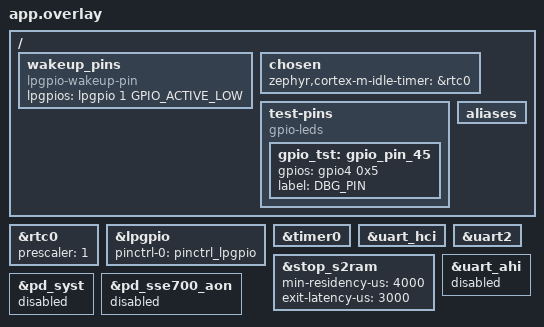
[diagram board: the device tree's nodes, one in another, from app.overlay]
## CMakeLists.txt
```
# Copyright (C) Alif Semiconductor - All Rights Reserved.
# Use, distribution and modification of this code is permitted under the
# terms stated in the Alif Semiconductor Software License Agreement
#
# You should have received a copy of the Alif Semiconductor Software
# License Agreement with this file. If not, please write to:
# contact@alifsemi.com, or visit: https://alifsemi.com/license

cmake_minimum_required(VERSION 3.20.0)
find_package(Zephyr REQUIRED HINTS $ENV{ZEPHYR_BASE})
project(ble_testapp)

target_sources(app PRIVATE
    src/main.c
    src/appl_shell.c
    src/power_mgr.c
    src/ble_handler.c
    src/power_shell.c
)
```

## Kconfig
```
# Copyright (C) Alif Semiconductor - All Rights Reserved.
# Use, distribution and modification of this code is permitted under the
# terms stated in the Alif Semiconductor Software License Agreement
#
# You should have received a copy of the Alif Semiconductor Software
# License Agreement with this file. If not, please write to:
# contact@alifsemi.com, or visit: https://alifsemi.com/license

source "Kconfig.zephyr"

config DATA_STRING_LENGTH
	int "Data string size"
	range 5 250
	default 243
	help
	  Defines how many bytes will be sent in a notification


menu "Logging"

module = MAIN
module-str = main
source "subsys/logging/Kconfig.template.log_config"

endmenu # "Logging"
```

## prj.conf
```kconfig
# Copyright (C) Alif Semiconductor - All Rights Reserved.
# Use, distribution and modification of this code is permitted under the
# terms stated in the Alif Semiconductor Software License Agreement
#
# You should have received a copy of the Alif Semiconductor Software
# License Agreement with this file. If not, please write to:
# contact@alifsemi.com, or visit: https://alifsemi.com/license

CONFIG_BT=y
CONFIG_BT_CUSTOM=y
CONFIG_ASSERT=y
CONFIG_IDLE_STACK_SIZE=2048
CONFIG_COUNTER=y

CONFIG_COUNTER_RTC_SNPS_DW=y
CONFIG_ALIF_POWER_MGR_SHELL=y

CONFIG_PM=y
CONFIG_PM_DEVICE=y
CONFIG_POWER_DOMAIN=y
CONFIG_PM_S2RAM=y
CONFIG_PM_SAU_SAVE_RESTORE=y

CONFIG_SYS_CLOCK_TICKS_PER_SEC=1000
CONFIG_STDOUT_CONSOLE=y
CONFIG_PRINTK=y
CONFIG_POWEROFF=y
CONFIG_BOOT_BANNER=n

CONFIG_SHELL=y
CONFIG_SHELL_AUTOSTART=n
CONFIG_ALIF_TESTCOMMANDS_SHELL=y

CONFIG_LOG=y
# application logging level
CONFIG_MAIN_LOG_LEVEL_INF=y

CONFIG_ALIF_PM_SLEEP_ENABLE=1

####### Configuration supported with the upddated Secure Enclave software
CONFIG_ALIF_EXT_WAKEUP_TIME=0
CONFIG_ALIF_OSC_WAKEUP_TIME=1700
CONFIG_ALIF_RM_WAKEUP_TIME=0
CONFIG_ALIF_EXT_WARMBOOT_WAKEUP_TIME=1700
CONFIG_SE_SERVICE_INIT_PRIORITY=1
CONFIG_KERNEL_INIT_PRIORITY_DEFAULT=0
CONFIG_GPIO_INIT_PRIORITY=40

CONFIG_ALIF_MAX_SLEEP_CLOCK_DRIFT=252
CONFIG_ALIF_MAX_ACTIVE_CLOCK_DRIFT=252

CONFIG_DATA_STRING_LENGTH=243
CONFIG_CORTEX_M_SYSTICK_LPM_TIMER_HOOKS=y

# Increase shell max commands so that we can set run_cfg and off_cfg
CONFIG_SHELL_ARGC_MAX=32
CONFIG_SHELL_CMD_BUFF_SIZE=384
```

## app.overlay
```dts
/* Copyright (C) Alif Semiconductor - All Rights Reserved.
 * Use, distribution and modification of this code is permitted under the
 * terms stated in the Alif Semiconductor Software License Agreement
 *
 * You should have received a copy of the Alif Semiconductor Software
 * License Agreement with this file. If not, please write to:
 * contact@alifsemi.com, or visit: https://alifsemi.com/license
 */

&rtc0 {
	/* Set the counter to increment every 1sec */
	prescaler = <1>;
	status = "okay";
};

&lpgpio {
	pinctrl-0 = < &pinctrl_lpgpio >;
	pinctrl-names = "default";
	status = "okay";
};

/ {
	wakeup_pins: wakeup_pins {
		compatible = "lpgpio-wakeup-pin";
		/* Use only P15_1 as p15_0 has some issues */
		lpgpios = <&lpgpio 1 GPIO_ACTIVE_LOW>;
	};
};

/* LPTimer0 */
&timer0 {
	status = "okay";
};

&uart_hci {
	status = "okay";
};

/* Sleep pincontrol needs to be removed as it causes a extra characters on output and input
 */

&uart2 {
	/*clocks = <&clockctrl ALIF_UART2_38M4_CLK>;*/
	status = "okay";
	/delete-property/ pinctrl-1; // = <&pinctrl_uart2_sleep>;
	pinctrl-names = "default";
};

&stop_s2ram {
	min-residency-us = <4000>;
	exit-latency-us = <3000>;
	status = "okay";
};

/ {
	chosen {
		zephyr,cortex-m-idle-timer = &rtc0;
	};

	test-pins {
		/* Use DK's green LED (P4.5) as a debug pin */
		compatible = "gpio-leds";
		gpio_tst: gpio_pin_45 {
			gpios = < &gpio4 0x5 0x0 >;
			label = "DBG_PIN";
		};
	};

	aliases {
		/* Enable this for the debugging output */
		/* debug-pin = &gpio_tst; */
	};
};

/* Disable unused default components */

&uart_ahi {
	status = "disabled";
};

/* TODO: these do nothing... to be resolved */
&pd_syst {
	status = "disabled";
};

&pd_sse700_aon {
	status = "disabled";
};
```

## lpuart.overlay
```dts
/* Copyright (C) Alif Semiconductor - All Rights Reserved.
 * Use, distribution and modification of this code is permitted under the
 * terms stated in the Alif Semiconductor Software License Agreement
 *
 * You should have received a copy of the Alif Semiconductor Software
 * License Agreement with this file. If not, please write to:
 * contact@alifsemi.com, or visit: https://alifsemi.com/license
 */

&uart2 {
	status = "disabled";
};

/* must override default pinctrl to use P7_0 instead of P2_0 for RX */
&pinctrl_lpuart {
	group0 {
		pinmux = <PIN_P7_0__LPUART_RX_B>,
				<PIN_P7_1__LPUART_TX_B>;
	};
};

&lpuart {
	current-speed = <115200>;
	dlf = <13>;
	/*/delete-property/ dlf;*/
	status = "okay";
	/delete-property/ pinctrl-1; // = <&pinctrl_lpuart_sleep>;
	pinctrl-names = "default";
};

/ {
	chosen {
		zephyr,console = &lpuart;
		zephyr,shell-uart = &lpuart;
		zephyr,uart-mcumgr = &lpuart;
	};
};
```

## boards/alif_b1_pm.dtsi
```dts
/*
 * Copyright (c) 2024 Alif Semiconductor
 * SPDX-License-Identifier: Apache-2.0
 */

&rtc0 {
	/* Set the counter to increment every 1sec */
	prescaler = <1>;
	status = "okay";
};

&lpgpio {
	pinctrl-0 = < &pinctrl_lpgpio >;
	pinctrl-names = "default";
	status = "okay";
};

/ {
	wakeup_pins: wakeup_pins {
		compatible = "lpgpio-wakeup-pin";
		/* Use only P15_1 as p15_0 has some issues */
		lpgpios = <&lpgpio 1 GPIO_ACTIVE_LOW>;
	};
};

/* LPTimer0 */
&timer0 {
	status = "okay";
};

&uart_hci {
	status = "okay";
};

&uart2 {
	/*clocks = <&clockctrl ALIF_UART2_38M4_CLK>;*/
	status = "okay";
};

&stop_s2ram {
	min-residency-us = <4000>;
	exit-latency-us = <3000>;
	status = "okay";
};

/ {
	chosen {
		zephyr,cortex-m-idle-timer = &rtc0;
	};

	test-pins {
		/* Use DK's green LED (P4.5) as a debug pin */
		compatible = "gpio-leds";
		gpio_tst: gpio_pin_45 {
			gpios = < &gpio4 0x5 0x0 >;
			label = "DBG_PIN";
		};
	};

	aliases {
		/* Enable this for the debugging output */
		/* debug-pin = &gpio_tst; */
	};
};

/* Disable unused default components */

&uart_ahi {
	status = "disabled";
};

/* TODO: these do nothing... to be resolved */
&pd_syst {
	status = "disabled";
};

&pd_sse700_aon {
	status = "disabled";
};
```

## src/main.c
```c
/* Copyright (C) Alif Semiconductor - All Rights Reserved.
 * Use, distribution and modification of this code is permitted under the
 * terms stated in the Alif Semiconductor Software License Agreement
 *
 * You should have received a copy of the Alif Semiconductor Software
 * License Agreement with this file. If not, please write to:
 * contact@alifsemi.com, or visit: https://alifsemi.com/license
 */

#include <zephyr/kernel.h>
#include <zephyr/logging/log.h>

#include <zephyr/device.h>
#include <zephyr/drivers/gpio.h>
#include <zephyr/init.h>
#include <zephyr/pm/pm.h>
#include <zephyr/pm/policy.h>
#include <zephyr/sys/poweroff.h>
#include <zephyr/drivers/counter.h>
#include <zephyr/drivers/uart.h>
#include <cmsis_core.h>
#include <soc_common.h>
#include <se_service.h>
#include <es0_power_manager.h>

#include "ke_mem.h"

#include "appl_shell.h"
#include "power_mgr.h"
#include "ble_handler.h"

#if !defined(CONFIG_SOC_SERIES_B1)
#error "Application works only with B1 devices"
#endif

static volatile bool wakeup_status;
static volatile int run_profile_error;

/* Macros */
LOG_MODULE_REGISTER(main, CONFIG_MAIN_LOG_LEVEL);

/*
 * CRITICAL: Must run at PRE_KERNEL_1 to restore SYSTOP before peripherals initialize.
 *
 * On cold boot: SYSTOP is already ON by default, safe to call.
 * On SOFT_OFF wakeup: SYSTOP is OFF, must restore BEFORE peripherals access registers.
 */
SYS_INIT(app_set_run_params, PRE_KERNEL_1, 3);

/**
 * PM Notifier callback for power state entry
 */
static void pm_notify_state_entry(enum pm_state const state)
{
	/* TODO: enable when this is needed */
	/*
	 * const struct pm_state_info *next_state = pm_state_next_get(0);
	 * uint8_t substate_id = next_state ? next_state->substate_id : 0;
	 */

	switch (state) {
	case PM_STATE_SUSPEND_TO_RAM:
	case PM_STATE_SOFT_OFF:
		break;
	default:
		__ASSERT(false, "Entering unknown power state %d", state);
		LOG_ERR("Entering unknown power state %d", state);
		break;
	}
}

/**
 * PM Notifier callback called BEFORE devices are resumed
 *
 * This restores SE run configuration when resuming from S2RAM states.
 * Note: For SOFT_OFF, the system resets completely and app_set_run_params()
 * runs during normal PRE_KERNEL_1 initialization, so this callback is not needed.
 */
static void pm_notify_pre_device_resume(enum pm_state const state)
{
	wakeup_status = get_wakeup_irq_status();

	switch (state) {
	case PM_STATE_SUSPEND_TO_RAM: {
		run_profile_error = app_set_run_params();
		break;
	}
	case PM_STATE_SOFT_OFF: {
		/* No action needed - SOFT_OFF causes reset, not resume */
		break;
	}
	default: {
		__ASSERT(false, "Pre-resume for unknown power state %d", state);
		LOG_ERR("Pre-resume for unknown power state %d", state);
		break;
	}
	}
}

/**
 * PM Notifier structure
 */
static struct pm_notifier app_pm_notifier = {
	.state_entry = pm_notify_state_entry,
	.pre_device_resume = pm_notify_pre_device_resume,
};

/*
 * This function will be invoked in the PRE_KERNEL_1 phase of the init
 * routine to prevent sleep during startup.
 */
static int app_pre_kernel_init(void)
{
	/* Register PM notifier callbacks */
	pm_notifier_register(&app_pm_notifier);

	app_prevent_off();

	return 0;
}
SYS_INIT(app_pre_kernel_init, PRE_KERNEL_1, 39);

#if defined(CONFIG_CORTEX_M_SYSTICK_LPM_TIMER_HOOKS)

static uint32_t idle_timer_pre_idle;

/* Idle timer used for timer while entering the idle state */
static const struct device *idle_timer = DEVICE_DT_GET(DT_CHOSEN(zephyr_cortex_m_idle_timer));
/**
 * To simplify the driver, implement the callout to Counter API
 * as hooks that would be provided by platform drivers if
 * CONFIG_CORTEX_M_SYSTICK_LPM_TIMER_HOOKS was selected instead.
 */
void z_cms_lptim_hook_on_lpm_entry(uint64_t max_lpm_time_us)
{

	/* Store current value of the selected timer to calculate a
	 * difference in measurements after exiting the idle state.
	 */
	counter_get_value(idle_timer, &idle_timer_pre_idle);
	/**
	 * Disable the counter alarm in case it was already running.
	 */
	/* counter_cancel_channel_alarm(idle_timer, 0); */

	/* Set the alarm using timer that runs the idle.
	 * Needed rump-up/setting time, lower accurency etc. should be
	 * included in the exit-latency in the power state definition.
	 */

	struct counter_alarm_cfg cfg = {
		.callback = NULL,
		.ticks = counter_us_to_ticks(idle_timer, max_lpm_time_us) + idle_timer_pre_idle,
		.user_data = NULL,
		.flags = COUNTER_ALARM_CFG_ABSOLUTE,
	};
	counter_set_channel_alarm(idle_timer, 0, &cfg);
}

uint64_t z_cms_lptim_hook_on_lpm_exit(void)
{
	/**
	 * Calculate how much time elapsed according to counter.
	 */
	uint32_t idle_timer_post, idle_timer_diff;

	counter_get_value(idle_timer, &idle_timer_post);

	/**
	 * Check for counter timer overflow
	 * (TODO: this doesn't work for downcounting timers!)
	 */
	if (idle_timer_pre_idle > idle_timer_post) {
		idle_timer_diff = (counter_get_top_value(idle_timer) - idle_timer_pre_idle) +
				  idle_timer_post + 1;
	} else {
		idle_timer_diff = idle_timer_post - idle_timer_pre_idle;
	}

	return (uint64_t)counter_ticks_to_us(idle_timer, idle_timer_diff);
}
#endif /* CONFIG_CORTEX_M_SYSTICK_LPM_TIMER_COUNTER */

int main(void)
{
	if (is_cold_boot()) {
		int ret = pwm_init();

		if (ret) {
			LOG_ERR("pwm_init failed: %d", ret);
			return ret;
		}

		ret = set_off_profile(PM_STATE_MODE_STOP);

		if (ret) {
			LOG_ERR("off profile set failed. error: %d", ret);
			return ret;
		}
		printk("BLE testapp cold start\n");
	}

	appl_wait_to_continue();

	int ret = ble_init();

	if (ret) {
		return ret;
	}

	if (appl_allow_sleep()) {
		app_ready_for_sleep();
	}

	while (1) {
		/* checks for whether sleep period is done */
		appl_allow_sleep();

		if (!ble_is_connected()) {
			k_sleep(K_MSEC(ble_rtc_connected_wakeup));
		} else {
			k_sleep(K_MSEC(ble_rtc_wakeup));
		}
	}
	return 0;
}
```

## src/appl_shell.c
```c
/* Copyright (C) Alif Semiconductor - All Rights Reserved.
 * Use, distribution and modification of this code is permitted under the
 * terms stated in the Alif Semiconductor Software License Agreement
 *
 * You should have received a copy of the Alif Semiconductor Software
 * License Agreement with this file. If not, please write to:
 * contact@alifsemi.com, or visit: https://alifsemi.com/license
 */

#include <zephyr/kernel.h>
#include <zephyr/shell/shell.h>
#include <zephyr/shell/shell_uart.h>
#include <zephyr/logging/log.h>
#include <stdlib.h>
#include "power_mgr.h"
#include "ble_handler.h"

LOG_MODULE_DECLARE(main, CONFIG_MAIN_LOG_LEVEL);

static struct k_sem waiting_semaphore;
static bool __attribute__((noinit)) force_ble_restart;
static bool __attribute__((noinit)) skip_wait;
static uint32_t __attribute__((noinit)) wakeup_time;

uint32_t ble_rtc_wakeup __attribute__((noinit));
uint32_t ble_rtc_connected_wakeup __attribute__((noinit));
uint16_t reset_after_sleep __attribute__((noinit));
enum lp_counter_source counter_source = -1;

void appl_shell_reset(void)
{
	skip_wait = false;
	force_ble_restart = false;
	wakeup_time = 0;
	ble_adv_int_min = 1000;
	ble_adv_int_max = 1000;
	ble_conn_int_min = 800;
	ble_conn_int_max = 800;
	ble_rtc_wakeup = 20000;
	strncpy(app_shell_device_name, "APPL_SHL", DEVICE_NAME_LEN - 1);
	app_shell_device_name[8] = 0;
	reset_after_sleep = 0;
}

void appl_shell_init(void)
{
	/* Mark a cold boot */
	appl_shell_reset();
	k_sem_init(&waiting_semaphore, 0, 1);
}

static int app_shell_init(void)
{
	/* If we are sleeping dont set the shell prompt off */
	const struct shell *shell = shell_backend_uart_get_ptr();

	if (!shell) {
		return 0;
	}
	shell_start(shell);
	appl_shell_init();

	return 0;
}

SYS_INIT(app_shell_init, APPLICATION, 1);

int64_t param_get_int(size_t argc, char **argv, char *p_param, int def_value)
{
	if (p_param && argc > 1) {
		for (int n = 0; n < (argc - 1); n++) {
			if (strcmp(argv[n], p_param) == 0) {
				return strtoll(argv[n + 1], NULL, 0);
			}
		}
	}
	return def_value;
}

char *param_get_char(size_t argc, char **argv, char *p_param, char *def_value)
{
	if (p_param && argc > 1) {
		for (int n = 0; n < (argc - 1); n++) {
			if (strcmp(argv[n], p_param) == 0) {
				return argv[n + 1];
			}
		}
	}
	return def_value;
}

void appl_wait_to_continue(void)
{
	const struct shell *shell = shell_backend_uart_get_ptr();

	shell_print(shell, "BLE testapp started!\n");

	if (!skip_wait) {
		k_sem_take(&waiting_semaphore, K_FOREVER);
		LOG_INF("continuing.");
	}
}

/**
 * Application command functions
 **/
static int cmd_adv_int(const struct shell *shell, size_t argc, char **argv)
{
	ble_adv_int_min = param_get_int(argc, argv, "--min", ble_adv_int_min);
	ble_adv_int_max = param_get_int(argc, argv, "--max", ble_adv_int_max);

	shell_fprintf(shell, SHELL_VT100_COLOR_DEFAULT,
			"set advertisement interval min: %d max %d\n",
			ble_adv_int_min, ble_adv_int_max);
	return 0;
}
static int cmd_conn_int(const struct shell *shell, size_t argc, char **argv)
{
	ble_conn_int_min = param_get_int(argc, argv, "--min", ble_conn_int_min);
	ble_conn_int_max = param_get_int(argc, argv, "--max", ble_conn_int_max);

	shell_fprintf(shell, SHELL_VT100_COLOR_DEFAULT, "set connection interval min: %d max %d\n",
		      ble_conn_int_min, ble_conn_int_max);
	return 0;
}

static int cmd_int(const struct shell *shell, size_t argc, char **argv)
{
	unsigned long wakeup_time = strtoul(argv[1], 0, 10);

	if (wakeup_time) {
		ble_rtc_wakeup = wakeup_time;
	}
	ble_rtc_connected_wakeup =
		param_get_int(argc, argv, "--connected", ble_rtc_connected_wakeup);

	shell_fprintf(shell, SHELL_VT100_COLOR_DEFAULT, "set RTC wakeup: %d when connected %d\n",
		      ble_rtc_wakeup, ble_rtc_connected_wakeup);
	return 0;
}

static int cmd_continue(const struct shell *shell, size_t argc, char **argv)
{
	reset_after_sleep = param_get_int(argc, argv, "--reset_after", reset_after_sleep);
	skip_wait = true;
	k_sem_give(&waiting_semaphore);
	shell_print(shell, "BLEtestapp continue");
	return 0;
}

void appl_shell_sleep_period_end(void)
{
	if (reset_after_sleep) {
		const struct shell *shell = shell_backend_uart_get_ptr();
		int ret;

		appl_shell_reset();
		ret = ble_uninit();
		shell_print(shell, "BLE application is restarted %d", ret);
	}
}

static int cmd_sleep(const struct shell *shell, size_t argc, char **argv)
{
	uint32_t sleeptime_s = strtoul(argv[1], 0, 10);

	shell_print(shell, "start sleep cycle %d s", sleeptime_s);

	app_sleep_start(sleeptime_s);
	return 0;
}

static int cmd_set_name(const struct shell *shell, size_t argc, char **argv)
{
	if (skip_wait) {
		shell_error(shell, "Name must be set on POR, before continue is called.");
		return -ENOEXEC;
	}
	/* app_shell_device_name has null-ending as per cold boot init */
	strncpy(app_shell_device_name, argv[1],	DEVICE_NAME_LEN - 1);
	shell_print(shell, "BLE name set to %s", app_shell_device_name);
	return 0;
}

static int cmd_select_timer(const struct shell *shell, size_t argc, char **argv)
{
	if (!strcmp(argv[1], "LPRTC")) {
		counter_source = LPRTC;
		shell_print(shell, "Selected LPRTC as wakeup source");
	} else if (!strcmp(argv[1], "LPTIMER")) {
		counter_source = LPTIMER;
		shell_print(shell, "Selected LPTIMER as wakeup source");
	} else {
		shell_error(shell, "Select timer source from LPRTC and LPTIMER");
		return -ENOEXEC;
	}
	return 0;
}


static int cmd_set_offprofile(const struct shell *shell, size_t argc, char **argv)
{
	int ret;

	if (!strcmp(argv[1], "STOP")) {
		ret = set_off_profile(PM_STATE_MODE_STOP_1);

		if (ret) {
			shell_error(shell, "Failed to set off profile: %d", ret);
			return -ENOEXEC;
		}
		shell_print(shell, "Off profile set to STOP");
	} else if (!strcmp(argv[1], "IDLE")) {
		set_off_profile_configuration(PM_STATE_MODE_IDLE_1);
		current_offp.power_domains |= PD_SESS_MASK;
		ret = set_current_off_profile();

		if (ret) {
			shell_error(shell, "Failed to set off profile: %d", ret);
			return -ENOEXEC;
		}
		shell_print(shell, "Off profile set to IDLE");
	} else if (!strcmp(argv[1], "STANDBY")) {
		ret = set_off_profile(PM_STATE_MODE_STANDBY_1);

		if (ret) {
			shell_error(shell, "Failed to set off profile: %d", ret);
			return -ENOEXEC;
		}
		shell_print(shell, "Off profile set to STANDBY");
	} else {
		shell_error(shell, "Select off profile from STOP, IDLE, STANDBY");
		return -ENOEXEC;
	}
	return 0;
}

SHELL_STATIC_SUBCMD_SET_CREATE(
	sub_cmds,
	SHELL_CMD_ARG(adv-interval, NULL,
		      "configure advertisement interval --min <slots> --max <slots>", cmd_adv_int,
		      1, 10),
	SHELL_CMD_ARG(conn-interval, NULL,
		      "configure connection interval --min <slots> --max <slots>", cmd_conn_int, 1,
		      10),
	SHELL_CMD_ARG(interval, NULL,
		      "configure M55 wakeup interval <time in ms> --connected <time in ms>",
		      cmd_int, 1, 10),
	SHELL_CMD_ARG(continue, NULL, "Start ble application --reset_after <0/1>",
		cmd_continue, 1, 10),
	SHELL_CMD_ARG(sleep, NULL, "allow sleep in <seconds>", cmd_sleep, 2, 10),
	SHELL_CMD_ARG(init, NULL, "BLE stack initialize", cmd_sleep, 2, 10),
	SHELL_CMD_ARG(set-name, NULL, "set name for BLE <name>", cmd_set_name, 2, 10),
	SHELL_CMD_ARG(set_offprofile, NULL, "Set off profile", cmd_set_offprofile, 2, 10),
	SHELL_CMD_ARG(select_timer, NULL, "Select timer source <LPRTC/LPTIMER>",
		cmd_select_timer, 2, 10),
	SHELL_SUBCMD_SET_END);

SHELL_CMD_REGISTER(ble_appl, &sub_cmds, "Ble configuration commands", NULL);
```

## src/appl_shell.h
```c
/* Copyright (C) Alif Semiconductor - All Rights Reserved.
 * Use, distribution and modification of this code is permitted under the
 * terms stated in the Alif Semiconductor Software License Agreement
 *
 * You should have received a copy of the Alif Semiconductor Software
 * License Agreement with this file. If not, please write to:
 * contact@alifsemi.com, or visit: https://alifsemi.com/license
 */

extern uint16_t ble_adv_int_min;
extern uint16_t ble_adv_int_max;
extern uint16_t ble_conn_int_min;
extern uint16_t ble_conn_int_max;
extern uint32_t ble_rtc_wakeup;
extern uint32_t ble_rtc_connected_wakeup;
extern char app_shell_device_name[];

void appl_wait_to_continue(void);
bool appl_allow_sleep(void);
void cmd_appl_shell_init(void);
bool appl_restart_ble(void);
```

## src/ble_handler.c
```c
/* Copyright (C) Alif Semiconductor - All Rights Reserved.
 * Use, distribution and modification of this code is permitted under the
 * terms stated in the Alif Semiconductor Software License Agreement
 *
 * You should have received a copy of the Alif Semiconductor Software
 * License Agreement with this file. If not, please write to:
 * contact@alifsemi.com, or visit: https://alifsemi.com/license
 */

#include "ble_handler.h"

#include <errno.h>
#include <zephyr/kernel.h>
#include <zephyr/logging/log.h>

#include <se_service.h>
#include "alif_ble.h"
#include "gapm.h"
#include "gap_le.h"
#include "gapc_le.h"
#include "gapc_sec.h"
#include "gapm_le.h"
#include "gapm_le_adv.h"
#include "co_buf.h"
#include "prf.h"
#include "gatt_db.h"
#include "gatt_srv.h"

#include "appl_shell.h"
#include <zephyr/shell/shell.h>
#include <zephyr/shell/shell_uart.h>
#include <alif/bluetooth/bt_adv_data.h>
#include <alif/bluetooth/bt_scan_rsp.h>
#include "gapm_api.h"

LOG_MODULE_DECLARE(main, CONFIG_MAIN_LOG_LEVEL);

static uint8_t hello_arr[] = "HelloHello";
static uint8_t hello_arr_index __attribute__((noinit));

/* BLE configurations*/
char __attribute__((noinit)) app_shell_device_name[DEVICE_NAME_LEN];

uint16_t ble_adv_int_min __attribute__((noinit));
uint16_t ble_adv_int_max __attribute__((noinit));
uint16_t ble_conn_int_min __attribute__((noinit));
uint16_t ble_conn_int_max __attribute__((noinit));

/* Service Definitions */
#define ATT_128_PRIMARY_SERVICE    ATT_16_TO_128_ARRAY(GATT_DECL_PRIMARY_SERVICE)
#define ATT_128_INCLUDED_SERVICE   ATT_16_TO_128_ARRAY(GATT_DECL_INCLUDE)
#define ATT_128_CHARACTERISTIC     ATT_16_TO_128_ARRAY(GATT_DECL_CHARACTERISTIC)
#define ATT_128_CLIENT_CHAR_CFG    ATT_16_TO_128_ARRAY(GATT_DESC_CLIENT_CHAR_CFG)
/* HELLO SERVICE and attribute 128 bit UUIDs */
#define HELLO_UUID_128_SVC                                                                         \
	{0x12, 0x34, 0x56, 0x78, 0x90, 0x12, 0x23, 0x34,                                           \
	 0x45, 0x56, 0x67, 0x78, 0x89, 0x90, 0x00, 0x00}
#define HELLO_UUID_128_CHAR0                                                                       \
	{0x12, 0x34, 0x56, 0x78, 0x90, 0x12, 0x23, 0x34,                                           \
	 0x45, 0x56, 0x67, 0x78, 0x89, 0x15, 0x00, 0x00}
#define HELLO_UUID_128_CHAR1                                                                       \
	{0x12, 0x34, 0x56, 0x78, 0x90, 0x12, 0x23, 0x34,                                           \
	 0x45, 0x56, 0x67, 0x78, 0x89, 0x16, 0x00, 0x00}
#define HELLO_METAINFO_CHAR0_NTF_SEND 0x4321
#define ATT_16_TO_128_ARRAY(uuid)                                                                  \
	{(uuid) & 0xFF, (uuid >> 8) & 0xFF, 0, 0, 0, 0, 0, 0, 0, 0, 0, 0, 0, 0, 0, 0}

/* List of attributes in the service */
enum service_att_list {
	HELLO_IDX_SERVICE = 0,
	/* First characteristic is readable + supports notifications */
	HELLO_IDX_CHAR0_CHAR,
	HELLO_IDX_CHAR0_VAL,
	HELLO_IDX_CHAR0_NTF_CFG,
	/* Second characteristic is writable */
	HELLO_IDX_CHAR1_CHAR,
	HELLO_IDX_CHAR1_VAL,
	/* Number of items*/
	HELLO_IDX_NB,
};

static volatile bool conn_status __attribute__((noinit));
/* Store advertising activity index for re-starting after disconnection */
static volatile uint8_t conn_idx __attribute__((noinit));
static uint8_t adv_actv_idx __attribute__((noinit));
static struct service_env env __attribute__((noinit));

static volatile int run_profile_error;

static const char *device_name = app_shell_device_name;

/* Service UUID to pass into gatt_db_svc_add */
static const uint8_t hello_service_uuid[] = HELLO_UUID_128_SVC;

/* GATT database for the service */
static const gatt_att_desc_t hello_att_db[HELLO_IDX_NB] = {
	[HELLO_IDX_SERVICE] = {ATT_128_PRIMARY_SERVICE, ATT_UUID(16) | PROP(RD), 0},

	[HELLO_IDX_CHAR0_CHAR] = {ATT_128_CHARACTERISTIC, ATT_UUID(16) | PROP(RD), 0},
	[HELLO_IDX_CHAR0_VAL] = {HELLO_UUID_128_CHAR0, ATT_UUID(128) | PROP(RD) | PROP(N),
				 OPT(NO_OFFSET)},
	[HELLO_IDX_CHAR0_NTF_CFG] = {ATT_128_CLIENT_CHAR_CFG, ATT_UUID(16) | PROP(RD) | PROP(WR),
				     0},

	[HELLO_IDX_CHAR1_CHAR] = {ATT_128_CHARACTERISTIC, ATT_UUID(16) | PROP(RD), 0},
	[HELLO_IDX_CHAR1_VAL] = {HELLO_UUID_128_CHAR1, ATT_UUID(128) | PROP(WR),
				 OPT(NO_OFFSET) | sizeof(uint16_t)},
};

/**
 * Bluetooth stack configuration
 */
static gapm_config_t gapm_cfg = {
	.role = GAP_ROLE_LE_PERIPHERAL,
	.pairing_mode = GAPM_PAIRING_DISABLE,
	.privacy_cfg = 0,
	.renew_dur = 1500,
	.private_identity.addr = {0xCF, 0xFE, 0xFB, 0xDE, 0x11, 0x07},
	.irk.key = {0, 0, 0, 0, 0, 0, 0, 0, 0, 0, 0, 0, 0, 0, 0, 0},
	.gap_start_hdl = 0,
	.gatt_start_hdl = 0,
	.att_cfg = 0,
	.sugg_max_tx_octets = GAP_LE_MAX_OCTETS,
	.sugg_max_tx_time = GAP_LE_MAX_TIME,
	.tx_pref_phy = GAP_PHY_ANY,
	.rx_pref_phy = GAP_PHY_ANY,
	.tx_path_comp = 0,
	.rx_path_comp = 0,
	.class_of_device = 0,  /* BT Classic only */
	.dflt_link_policy = 0, /* BT Classic only */
};

/* Environment for the service */
struct service_env {
	uint16_t start_hdl;
	uint8_t user_lid;
	uint8_t char0_val[250];
	uint8_t char1_val;
	volatile bool ntf_ongoing;
	volatile uint16_t ntf_cfg;
};

static gapc_le_con_param_nego_with_ce_len_t app_preferred_connection_param = {.ce_len_min = 5,
									      .ce_len_max = 10,
									      .hdr.interval_min = 0,
									      .hdr.interval_max =
										      10,
									      .hdr.latency = 0,
									      .hdr.sup_to = 800};

/* function headers */
static uint16_t service_init(void);

/* Functions */

int ble_shell_reset(void)
{
	ble_adv_int_min = 1000;
	ble_adv_int_max = 1000;
	ble_conn_int_min = 800;
	ble_conn_int_max = 800;
	strncpy(app_shell_device_name, "test_shl", DEVICE_NAME_LEN - 1);
	app_shell_device_name[8] = 0;
	return 0;
}

SYS_INIT(ble_shell_reset, POST_KERNEL, 91);

/**
 * Bluetooth GAPM callbacks
 */
void on_gapc_proc_cmp_cb(uint8_t conidx, uint32_t metainfo, uint16_t status)
{
	LOG_INF("%s conn:%d status:%d\n", __func__, conidx, status);
}
static void app_connected_handler(uint8_t con_idx)
{
	const struct shell *shell = shell_backend_uart_get_ptr();
	uint16_t ret;

	conn_status = BT_CONN_STATE_CONNECTED;
	conn_idx = con_idx;
	ret = gapc_le_update_params(con_idx, 0, &app_preferred_connection_param,
				    on_gapc_proc_cmp_cb);

	shell_print(shell, "BLE Connected conn:%d", con_idx);
}

void app_connection_status_update(enum gapm_connection_event con_event, uint8_t con_idx,
				  uint16_t status)
{
	const struct shell *shell = shell_backend_uart_get_ptr();

	switch (con_event) {
	case GAPM_API_SEC_CONNECTED_KNOWN_DEVICE:
		app_connected_handler(con_idx);
		break;
	case GAPM_API_DEV_CONNECTED:
		app_connected_handler(con_idx);
		break;
	case GAPM_API_DEV_DISCONNECTED:
		conn_status = BT_CONN_STATE_DISCONNECTED;
		conn_idx = GAP_INVALID_CONIDX;
		shell_print(shell, "BLE disconnected conn:%d. Waiting new connection", con_idx);
		break;
	case GAPM_API_PAIRING_FAIL:
		shell_print(shell, "Connection pairing index %u fail for reason %u", con_idx,
			    status);
		break;
	}
}

static gapm_user_cb_t gapm_user_cb = {
	.connection_status_update = app_connection_status_update,
};

static uint16_t set_advertising_data(uint8_t actv_idx)
{
	bt_adv_data_set_name_auto(device_name, strlen(device_name));

	return bt_gapm_advertiment_data_set(actv_idx);
}

static uint16_t set_scan_data(uint8_t actv_idx)
{
	int ret;

	/* gatt service identifier */
	uint16_t svc[8] = {0xd123, 0xeabc, 0x785f, 0x1523, 0xefde, 0x1212, 0x1523, 0x0000};

	ret = bt_scan_rsp_set_tlv(GAP_AD_TYPE_COMPLETE_LIST_128_BIT_UUID, svc, sizeof(svc));
	if (ret) {
		LOG_ERR("Scan response UUID set fail %d", ret);
		return ATT_ERR_INSUFF_RESOURCE;
	}

	ret = bt_scan_rsp_data_set_name_auto(device_name, strlen(device_name));

	if (ret) {
		LOG_ERR("Scan response device name data fail %d", ret);
		return ATT_ERR_INSUFF_RESOURCE;
	}

	return bt_gapm_scan_response_set(actv_idx);
}

static uint16_t create_advertising(void)
{
	gapm_le_adv_create_param_t adv_create_params = {
		.prop = GAPM_ADV_PROP_UNDIR_CONN_MASK,
		.disc_mode = GAPM_ADV_MODE_GEN_DISC,
		.tx_pwr = 0,
		.filter_pol = GAPM_ADV_ALLOW_SCAN_ANY_CON_ANY,
		.prim_cfg = {
				.adv_intv_min = ble_adv_int_min,
				.adv_intv_max = ble_adv_int_max,
				.ch_map = ADV_ALL_CHNLS_EN,
				.phy = GAPM_PHY_TYPE_LE_1M,
			},
	};

	return bt_gapm_le_create_advertisement_service(GAPM_STATIC_ADDR, &adv_create_params, NULL,
						       &adv_actv_idx);
}

/* Add service to the stack */
static void server_configure(void)
{
	uint16_t err;

	err = service_init();

	if (err) {
		LOG_ERR("Error %u adding profile", err);
	}
}

/* Service callbacks */
static void on_att_read_get(uint8_t conidx, uint8_t user_lid, uint16_t token, uint16_t hdl,
			    uint16_t offset, uint16_t max_length)
{
	co_buf_t *p_buf = NULL;
	uint16_t status = GAP_ERR_NO_ERROR;
	uint16_t att_val_len = 0;
	void *att_val = NULL;

	do {
		if (offset != 0) {
			/* Long read not supported for any characteristics within this service */
			status = ATT_ERR_INVALID_OFFSET;
			break;
		}

		uint8_t att_idx = hdl - env.start_hdl;

		switch (att_idx) {
		case HELLO_IDX_CHAR0_VAL:
			att_val_len = CONFIG_DATA_STRING_LENGTH;
			uint8_t loop_count = (CONFIG_DATA_STRING_LENGTH / 5);

			if (CONFIG_DATA_STRING_LENGTH % 5) {
				loop_count += 1;
			}
			for (int i = 0; i < loop_count; i++) {
				memcpy(env.char0_val + i * 5, &hello_arr[hello_arr_index], 5);
			}
			att_val = env.char0_val;
			LOG_DBG("read hello text");
			break;

		case HELLO_IDX_CHAR0_NTF_CFG:
			att_val_len = sizeof(env.ntf_cfg);
			att_val = (void *)&env.ntf_cfg;
			break;

		default:
			break;
		}

		if (att_val == NULL) {
			status = ATT_ERR_REQUEST_NOT_SUPPORTED;
			break;
		}

		status = co_buf_alloc(&p_buf, GATT_BUFFER_HEADER_LEN, att_val_len,
				      GATT_BUFFER_TAIL_LEN);
		if (status != CO_BUF_ERR_NO_ERROR) {
			status = ATT_ERR_INSUFF_RESOURCE;
			break;
		}

		memcpy(co_buf_data(p_buf), att_val, att_val_len);
	} while (0);

	/* Send the GATT response */
	gatt_srv_att_read_get_cfm(conidx, user_lid, token, status, att_val_len, p_buf);
	if (p_buf != NULL) {
		co_buf_release(p_buf);
	}
}

static void on_att_val_set(uint8_t conidx, uint8_t user_lid, uint16_t token, uint16_t hdl,
			   uint16_t offset, co_buf_t *p_data)
{
	uint16_t status = GAP_ERR_NO_ERROR;

	do {
		if (offset != 0) {
			/* Long write not supported for any characteristics in this service */
			status = ATT_ERR_INVALID_OFFSET;
			break;
		}

		uint8_t att_idx = hdl - env.start_hdl;

		switch (att_idx) {
		case HELLO_IDX_CHAR1_VAL: {
			if (sizeof(env.char1_val) != co_buf_data_len(p_data)) {
				LOG_DBG("Incorrect buffer size");
				status = ATT_ERR_INVALID_ATTRIBUTE_VAL_LEN;
			} else {
				memcpy(&env.char1_val, co_buf_data(p_data), sizeof(env.char1_val));
				LOG_DBG("TOGGLE LED, state %d", env.char1_val);
			}
			break;
		}

		case HELLO_IDX_CHAR0_NTF_CFG: {
			if (sizeof(uint16_t) != co_buf_data_len(p_data)) {
				LOG_DBG("Incorrect buffer size");
				status = ATT_ERR_INVALID_ATTRIBUTE_VAL_LEN;
			} else {
				uint16_t cfg;

				memcpy(&cfg, co_buf_data(p_data), sizeof(uint16_t));
				if (PRF_CLI_START_NTF == cfg || PRF_CLI_STOP_NTFIND == cfg) {
					env.ntf_cfg = cfg;
				} else {
					/* Indications not supported */
					status = ATT_ERR_REQUEST_NOT_SUPPORTED;
				}
			}
			break;
		}

		default:
			status = ATT_ERR_REQUEST_NOT_SUPPORTED;
			break;
		}
	} while (0);

	/* Send the GATT write confirmation */
	gatt_srv_att_val_set_cfm(conidx, user_lid, token, status);
}

static void on_event_sent(uint8_t conidx, uint8_t user_lid, uint16_t metainfo, uint16_t status)
{
	if (metainfo == HELLO_METAINFO_CHAR0_NTF_SEND) {
		env.ntf_ongoing = false;
	}
}

static const gatt_srv_cb_t gatt_cbs = {
	.cb_att_event_get = NULL,
	.cb_att_info_get = NULL,
	.cb_att_read_get = on_att_read_get,
	.cb_att_val_set = on_att_val_set,
	.cb_event_sent = on_event_sent,
};

/*
 * Service functions
 */
static uint16_t service_init(void)
{
	uint16_t status;

	/* Register a GATT user */
	status = gatt_user_srv_register(CFG_MAX_LE_MTU, 0, &gatt_cbs, &env.user_lid);
	if (status != GAP_ERR_NO_ERROR) {
		return status;
	}

	/* Add the GATT service */
	status = gatt_db_svc_add(env.user_lid, SVC_UUID(128), hello_service_uuid, HELLO_IDX_NB,
				 NULL, hello_att_db, HELLO_IDX_NB, &env.start_hdl);
	if (status != GAP_ERR_NO_ERROR) {
		gatt_user_unregister(env.user_lid);
		return status;
	}

	return GAP_ERR_NO_ERROR;
}

int ble_init(void)
{
	/* Update preferred connection parameters */
	app_preferred_connection_param.hdr.interval_min = ble_conn_int_min;
	app_preferred_connection_param.hdr.interval_max = ble_conn_int_max;

	/* Start up bluetooth host stack. */
	uint16_t ble_status = alif_ble_enable(NULL);

	if (ble_status && ble_status != -EALREADY) {
		LOG_ERR("alif_ble_enable error %d", ble_status);
		return -1;
	}
	return 0;
}

int ble_start(void)
{
	uint16_t rc;
	/* BLE initialized first time */
	hello_arr_index = 0;
	conn_idx = GAP_INVALID_CONIDX;
	memset(&env, 0, sizeof(struct service_env));
	conn_status = BT_CONN_STATE_DISCONNECTED;

	/* Set a preferred connections params  */
	bt_gapm_preferred_connection_paras_set(&app_preferred_connection_param);
	/* Generate random address */
	se_service_get_rnd_num(&gapm_cfg.private_identity.addr[3], 3);
	/* Configure Bluetooth Stack */
	LOG_INF("Init gapm service");
	rc = bt_gapm_init(&gapm_cfg, &gapm_user_cb, device_name, strlen(device_name));
	if (rc) {
		LOG_ERR("gapm_configure error %u", rc);
		return -1;
	}

	server_configure();

	/* Create an advertising activity */
	rc = create_advertising();
	if (rc) {
		LOG_ERR("Advertisement create fail %u", rc);
		return -1;
	}

	rc = set_advertising_data(adv_actv_idx);
	if (rc) {
		LOG_ERR("Advertisement data set fail %u", rc);
		return -1;
	}

	rc = set_scan_data(adv_actv_idx);
	if (rc) {
		LOG_ERR("Scan response data set fail %u", rc);
		return -1;
	}

	rc = bt_gapm_advertisement_start(adv_actv_idx);
	if (rc) {
		LOG_ERR("Advertisement start fail %u", rc);
		return -1;
	}

	LOG_INF("start complete!");
	return 0;
}

int ble_uninit(void)
{
	conn_status = BT_CONN_STATE_DISCONNECTED;
	return alif_ble_disable();
}

bool ble_is_connected(void)
{
	return (BT_CONN_STATE_DISCONNECTED == BT_CONN_STATE_CONNECTED);
}

static int cmd_bt_disable(const struct shell *shell, size_t argc, char **argv)
{
	int ret;

	ble_shell_reset();
	ret = ble_uninit();
	shell_print(shell, "BLE application is restarted %d", ret);
	return 0;
}

static int cmd_bt_init(const struct shell *shell, size_t argc, char **argv)
{
	int ret = ble_init();

	shell_print(shell, "BLE stack init %d", ret);
	return 0;
}

static int cmd_bt_name(const struct shell *shell, size_t argc, char **argv)
{
	/* app_shell_device_name has null-ending as per cold boot init */
	strncpy(app_shell_device_name, argv[1], DEVICE_NAME_LEN - 1);
	shell_print(shell, "BLE name set to %s", app_shell_device_name);
	return 0;
}

static int cmd_bt_advertise(const struct shell *shell, size_t argc, char **argv)
{
	int ret;

	ret = ble_start();
	shell_print(shell, "BLE advertisement started %d", ret);
	return 0;
}

SHELL_STATIC_SUBCMD_SET_CREATE(
	sub_cmds,
	SHELL_CMD_ARG(init, NULL, "[none]", cmd_bt_init, 1, 10),
	SHELL_CMD_ARG(advertise, NULL, "<type: off, on, nconn>", cmd_bt_advertise, 1, 10),
	SHELL_CMD_ARG(disable, NULL, "[none]", cmd_bt_disable, 1, 10),
	SHELL_CMD_ARG(name, NULL, "[name]", cmd_bt_name, 2, 10),
	SHELL_SUBCMD_SET_END);
SHELL_CMD_REGISTER(bt, &sub_cmds, "bt - Bluetooth shell commands", NULL);
```

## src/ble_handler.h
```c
/* Copyright (C) Alif Semiconductor - All Rights Reserved.
 * Use, distribution and modification of this code is permitted under the
 * terms stated in the Alif Semiconductor Software License Agreement
 *
 * You should have received a copy of the Alif Semiconductor Software
 * License Agreement with this file. If not, please write to:
 * contact@alifsemi.com, or visit: https://alifsemi.com/license
 */

#include <inttypes.h>
#include <stdbool.h>

#define DEVICE_NAME_LEN 9
extern char app_shell_device_name[];

extern uint16_t ble_adv_int_min;
extern uint16_t ble_adv_int_max;
extern uint16_t ble_conn_int_min;
extern uint16_t ble_conn_int_max;

int ble_init(void);
int ble_start(void);
int ble_uninit(void);
bool ble_is_connected(void);
```

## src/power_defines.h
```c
/* Copyright (C) Alif Semiconductor - All Rights Reserved.
 * Use, distribution and modification of this code is permitted under the
 * terms stated in the Alif Semiconductor Software License Agreement
 *
 * You should have received a copy of the Alif Semiconductor Software
 * License Agreement with this file. If not, please write to:
 * contact@alifsemi.com, or visit: https://alifsemi.com/license
 */
#ifndef __POWER_DEFINES_H__
#define __POWER_DEFINES_H__

#include <zephyr/kernel.h>
#include <aipm.h>

enum lp_counter_source {
	LPRTC,
	LPTIMER,
};

#define SERAM_MEMORY_BLOCKS_IN_USE SERAM_1_MASK | SERAM_2_MASK | SERAM_3_MASK | SERAM_4_MASK

#define APP_RET_MEM_BLOCKS \
	SRAM4_1_MASK | SRAM4_2_MASK | SRAM4_3_MASK | SRAM4_4_MASK | SRAM5_1_MASK | SRAM5_2_MASK |  \
	SRAM5_3_MASK | SRAM5_4_MASK | SRAM5_5_MASK

#if DT_NODE_HAS_COMPAT_STATUS(DT_NODELABEL(timer0), snps_dw_timers, okay)
#define WAKEUP_SOURCE_LPTIMER	DT_NODELABEL(timer0)
#endif
#if DT_NODE_HAS_COMPAT_STATUS(DT_NODELABEL(rtc0), snps_dw_apb_rtc, okay)
#define WAKEUP_SOURCE_RTC		DT_NODELABEL(rtc0)
#endif
#if DT_NODE_HAS_COMPAT_STATUS(DT_NODELABEL(lpgpio), snps_designware_gpio, okay)
#define WAKEUP_SOURCE_LPGPIO	DT_NODELABEL(lpgpio)
#endif

#endif /* __POWER_DEFINES_H__ */
```

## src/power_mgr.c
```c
/* Copyright (C) Alif Semiconductor - All Rights Reserved.
 * Use, distribution and modification of this code is permitted under the
 * terms stated in the Alif Semiconductor Software License Agreement
 *
 * You should have received a copy of the Alif Semiconductor Software
 * License Agreement with this file. If not, please write to:
 * contact@alifsemi.com, or visit: https://alifsemi.com/license
 */

#include <zephyr/kernel.h>
#include <zephyr/logging/log.h>
#include <zephyr/pm/pm.h>
#include <zephyr/pm/policy.h>
#include <zephyr/drivers/counter.h>
#include <zephyr/shell/shell.h>
#include <zephyr/shell/shell_uart.h>
#include <cmsis_core.h>
#include <se_service.h>
#include "power_mgr.h"
#include "power_defines.h"
#include "ble_handler.h"

struct k_timer sleep_end_timer;
void sleep_period_end(struct k_timer *timer_id);
void sleep_period_done(struct k_work *work);

K_WORK_DEFINE(sleep_end_worker, sleep_period_done);

LOG_MODULE_DECLARE(main, CONFIG_MAIN_LOG_LEVEL);

extern enum lp_counter_source counter_source;
static const struct device *wakeup_dev;
static bool counter_started;

run_profile_t current_runp __attribute__((noinit));
off_profile_t current_offp __attribute__((noinit));
int16_t power_profile __attribute__((noinit));

static int power_mgr_init(void)
{
	counter_started = false;
	wakeup_dev = 0;
	return select_timer_source(LPRTC);
}

int select_timer_source(enum lp_counter_source source)
{
	int ret = 0;

	if (counter_source == source) {
		return 0;
	}

	if (counter_started) {
		ret = counter_stop(wakeup_dev);
		if (ret && ret != -EALREADY) {
			printk("failed to stop counter: %d", ret);
			return -1;
		}
		counter_started = false;
	}

	wakeup_dev = 0;

	if (source == LPRTC) {
#ifndef WAKEUP_SOURCE_RTC
		printk("Wakeup Device RTC not enabled in the dts");
		return -1;
#else
		wakeup_dev = DEVICE_DT_GET(WAKEUP_SOURCE_RTC);
#endif
	} else if (source == LPTIMER) {
#ifndef WAKEUP_SOURCE_LPTIMER
		printk("Wakeup Device LPTIMER not enabled in the dts");
		return -1;
#else
		wakeup_dev = DEVICE_DT_GET(WAKEUP_SOURCE_LPTIMER);
#endif
	} else {
		LOG_ERR("Invalid timer source selected");
		return -1;
	}

	if (!device_is_ready(wakeup_dev)) {
		printk("%s: device not ready", wakeup_dev->name);
		return -1;
	}

	ret = counter_start(wakeup_dev);

	if (ret && ret != -EALREADY) {
		printk("failed to start counter: %d", ret);
		return -1;
	}

	counter_source = source;
	counter_started = true;
	get_default_off_cfg(&current_offp);
	ret = set_off_profile(PM_STATE_MODE_STOP_1);

	get_default_run_cfg(&current_runp);

	if (ret) {
		LOG_ERR("off profile set failed. error: %d", ret);
	}
	k_timer_init(&sleep_end_timer, sleep_period_end, NULL);

	return 0;
}
SYS_INIT(power_mgr_init, POST_KERNEL, 99);

void app_ready_for_sleep(void)
{
	pm_policy_state_lock_put(PM_STATE_SOFT_OFF, PM_ALL_SUBSTATES);
	pm_policy_state_lock_put(PM_STATE_SUSPEND_TO_RAM, PM_ALL_SUBSTATES);
}

void app_prevent_off(void)
{
	pm_policy_state_lock_get(PM_STATE_SOFT_OFF, PM_ALL_SUBSTATES);
	pm_policy_state_lock_get(PM_STATE_SUSPEND_TO_RAM, PM_ALL_SUBSTATES);
}

void sleep_period_done(struct k_work *work)
{
	const struct shell *shell = shell_backend_uart_get_ptr();

	shell_print(shell, "sleep period done.");
}

void sleep_period_end(struct k_timer *timer_id)
{
	app_prevent_off();
	k_work_submit(&sleep_end_worker);
}

void app_sleep_start(uint32_t time_s)
{
	k_timer_start(&sleep_end_timer, K_SECONDS(time_s), K_NO_WAIT);
	app_ready_for_sleep();
}

int set_current_off_profile(void)
{
	int ret = se_service_set_off_cfg(&current_offp);

	if (ret) {
		LOG_ERR("SE: set_off_cfg failed = %d", ret);
	}
	return ret;
}

int set_off_profile_configuration(const enum pm_state_mode_type pm_mode)
{
	/* Set default for stop mode with RTC wakeup support */
	current_offp.power_domains = PD_VBAT_AON_MASK;
/* If CONFIG_FLASH_BASE_ADDRESS is zero application run from itcm and no MRAM needed */
#if (CONFIG_FLASH_BASE_ADDRESS == 0)
	current_offp.memory_blocks = 0;
#else
	current_offp.memory_blocks = MRAM_MASK;
#endif
	current_offp.memory_blocks |= SERAM_MEMORY_BLOCKS_IN_USE;
	current_offp.memory_blocks |= APP_RET_MEM_BLOCKS;
	current_offp.dcdc_voltage = 775;
	current_offp.vdd_ioflex_3V3 = IOFLEX_LEVEL_1V8;

	switch (pm_mode) {
	case PM_STATE_MODE_IDLE_1:
	case PM_STATE_MODE_STANDBY_1:
		current_offp.power_domains |= PD_SSE700_AON_MASK;
		current_offp.ip_clock_gating = 0;
		current_offp.phy_pwr_gating = 0;
		current_offp.dcdc_mode = DCDC_MODE_PFM_AUTO;
		break;
	case PM_STATE_MODE_STOP_1:
		current_offp.ip_clock_gating = 0;
		current_offp.phy_pwr_gating = 0;
		current_offp.dcdc_mode = DCDC_MODE_OFF;
		break;
	case PM_STATE_MODE_GO_1:
	case PM_STATE_MODE_GO_2:
	case PM_STATE_MODE_GO_3:
	case PM_STATE_MODE_GO_4:
	case PM_STATE_MODE_GO_5:
	case PM_STATE_MODE_READY_1:
	case PM_STATE_MODE_READY_2:
	case PM_STATE_MODE_IDLE_2:
	case PM_STATE_MODE_STOP_2:
	case PM_STATE_MODE_STOP_3:
	case PM_STATE_MODE_STOP_4:
	case PM_STATE_MODE_STOP_5:
		break;
	}

	current_offp.aon_clk_src = CLK_SRC_LFXO;
	current_offp.stby_clk_src = CLK_SRC_HFRC;
	current_offp.stby_clk_freq = SCALED_FREQ_RC_STDBY_0_075_MHZ;
	if (counter_source == LPRTC) {
		current_offp.ewic_cfg = EWIC_RTC_A;
		current_offp.wakeup_events = WE_LPRTC;
	} else if (counter_source == LPTIMER) {
		current_offp.ewic_cfg = EWIC_VBAT_TIMER;
		current_offp.wakeup_events = WE_LPTIMER;
	} else {
		LOG_ERR("Invalid timer source selected");
		return -1;
	}
	current_offp.vtor_address = SCB->VTOR;
	current_offp.vtor_address_ns = SCB->VTOR;

	return 0;
}

int set_off_profile(const enum pm_state_mode_type pm_mode)
{

	set_off_profile_configuration(pm_mode);
	return set_current_off_profile();
}

void get_default_run_cfg(run_profile_t *runp)
{
	runp->power_domains = PD_VBAT_AON_MASK | PD_SYST_MASK | PD_SSE700_AON_MASK;
	runp->power_domains |= PD_SESS_MASK | PD_DBSS_MASK;
	runp->dcdc_voltage = 775;
	runp->dcdc_mode = DCDC_MODE_PFM_FORCED;
	runp->aon_clk_src = CLK_SRC_LFXO;
	runp->run_clk_src = CLK_SRC_PLL;
	runp->cpu_clk_freq = CLOCK_FREQUENCY_160MHZ;
	runp->phy_pwr_gating = 0;
	runp->ip_clock_gating = 0;
	runp->vdd_ioflex_3V3 = IOFLEX_LEVEL_1V8;
	runp->scaled_clk_freq = SCALED_FREQ_RC_ACTIVE_76_8_MHZ;

	runp->memory_blocks = MRAM_MASK;
	runp->memory_blocks |= SERAM_MEMORY_BLOCKS_IN_USE;
	runp->memory_blocks |= APP_RET_MEM_BLOCKS;

	if (IS_ENABLED(CONFIG_MIPI_DSI)) {
		runp->phy_pwr_gating |= MIPI_TX_DPHY_MASK | MIPI_RX_DPHY_MASK;
		runp->phy_pwr_gating |= MIPI_PLL_DPHY_MASK;
		runp->ip_clock_gating |= CDC200_MASK | MIPI_DSI_MASK | GPU_MASK;
	}
}

void get_default_off_cfg(off_profile_t *offp)
{
	/* Default is STOP mode */
	offp->power_domains = PD_VBAT_AON_MASK;
/* If CONFIG_FLASH_BASE_ADDRESS is zero application run from itcm and no MRAM needed */
#if (CONFIG_FLASH_BASE_ADDRESS == 0)
	offp->memory_blocks = 0;
#else
	offp->memory_blocks = MRAM_MASK;
#endif
	offp->memory_blocks |= SERAM_MEMORY_BLOCKS_IN_USE;
	offp->memory_blocks |= APP_RET_MEM_BLOCKS;
	offp->dcdc_voltage = 775;
	offp->ip_clock_gating = 0;
	offp->phy_pwr_gating = 0;
	offp->vdd_ioflex_3V3 = IOFLEX_LEVEL_1V8;
	offp->dcdc_mode = DCDC_MODE_OFF;
	offp->aon_clk_src = CLK_SRC_LFXO;
	offp->stby_clk_src = CLK_SRC_HFRC;
	offp->stby_clk_freq = SCALED_FREQ_RC_STDBY_0_075_MHZ;
	if (counter_source == LPRTC) {
		offp->ewic_cfg = EWIC_RTC_A;
		offp->wakeup_events = WE_LPRTC;
	} else if (counter_source == LPTIMER) {
		offp->ewic_cfg = EWIC_VBAT_TIMER;
		offp->wakeup_events = WE_LPTIMER;
	} else {
		LOG_ERR("Invalid timer source selected");
	}
	offp->vtor_address = SCB->VTOR;
	offp->vtor_address_ns = SCB->VTOR;
}

/**
 * Set the RUN profile parameters for this application.
 */
int app_set_run_params(void)
{
	int ret = se_service_set_run_cfg(&current_runp);

	return ret;
}
```

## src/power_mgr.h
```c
/* Copyright (C) Alif Semiconductor - All Rights Reserved.
 * Use, distribution and modification of this code is permitted under the
 * terms stated in the Alif Semiconductor Software License Agreement
 *
 * You should have received a copy of the Alif Semiconductor Software
 * License Agreement with this file. If not, please write to:
 * contact@alifsemi.com, or visit: https://alifsemi.com/license
 */

 #include "power_defines.h"

  /* Power modes. Based on E8 power modes so same tests can be run with E8 and B1. */
enum pm_state_mode_type {
	PM_STATE_MODE_GO_1,
	PM_STATE_MODE_GO_2,
	PM_STATE_MODE_GO_3,
	PM_STATE_MODE_GO_4,
	PM_STATE_MODE_GO_5,
	PM_STATE_MODE_READY_1,
	PM_STATE_MODE_READY_2,
	PM_STATE_MODE_IDLE_1,
	PM_STATE_MODE_IDLE_2,
	PM_STATE_MODE_STANDBY_1,
	PM_STATE_MODE_STOP_1,
	PM_STATE_MODE_STOP_2,
	PM_STATE_MODE_STOP_3,
	PM_STATE_MODE_STOP_4,
	PM_STATE_MODE_STOP_5
};
extern run_profile_t current_runp;
extern off_profile_t current_offp;
extern int16_t power_profile;

int select_timer_source(enum lp_counter_source source);
void app_sleep_start(uint32_t time_s);
void get_default_run_cfg(run_profile_t *runp);
void get_default_off_cfg(off_profile_t *offp);
int set_current_off_profile(void);
int set_off_profile(const enum pm_state_mode_type pm_mode);
int set_off_profile_configuration(const enum pm_state_mode_type pm_mode);
int app_set_run_params(void);
void app_prevent_off(void);
```

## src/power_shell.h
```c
/* Copyright (C) Alif Semiconductor - All Rights Reserved.
 * Use, distribution and modification of this code is permitted under the
 * terms stated in the Alif Semiconductor Software License Agreement
 *
 * You should have received a copy of the Alif Semiconductor Software
 * License Agreement with this file. If not, please write to:
 * contact@alifsemi.com, or visit: https://alifsemi.com/license
 */

 #include <aipm.h>
```
